AUTOSAR XML (schema 314)
package /ComponentType
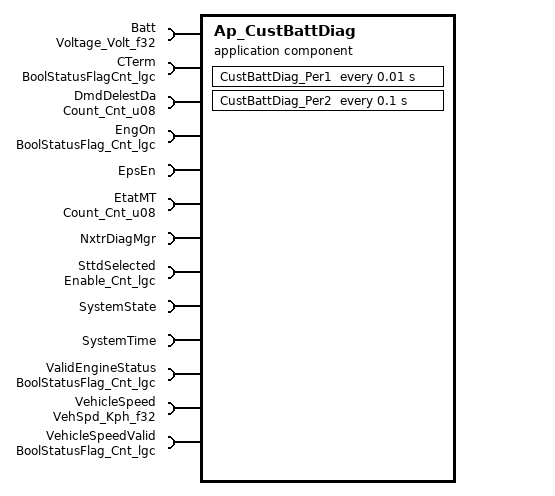
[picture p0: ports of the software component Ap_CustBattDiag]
  application software component type Ap_CustBattDiag
    13 x require port:
      Batt: unqueued-receiver-com-spec{data-element=Volt_f32, init-value=D_ZERO_ULS_F32}, required-interface=Voltage_Volt_f32
      CTerm: unqueued-receiver-com-spec{data-element=Cnt_lgc, init-value=D_FALSE_CNT_LGC}, required-interface=BoolStatusFlagCnt_lgc
      DmdDelestDa: unqueued-receiver-com-spec{data-element=Cnt_u08, init-value=D_ZERO_CNT_U8}, required-interface=Count_Cnt_u08
      EngOn: unqueued-receiver-com-spec{data-element=Cnt_lgc, init-value=D_FALSE_CNT_LGC}, required-interface=BoolStatusFlag_Cnt_lgc
      EpsEn: client-com-spec=OP_GET, required-interface=EpsEn
      EtatMT: unqueued-receiver-com-spec{data-element=Cnt_u08, init-value=D_ZERO_CNT_U8}, required-interface=Count_Cnt_u08
      NxtrDiagMgr: required-com-specs=[GetNTCActive, GetNTCFailed, GetNTCStatus, SetNTCStatus], required-interface=NxtrDiagMgr
      SttdSelected: unqueued-receiver-com-spec{data-element=Cnt_lgc, init-value=D_FALSE_CNT_LGC}, required-interface=Enable_Cnt_lgc
      SystemState: required-interface=SystemState
      SystemTime: required-interface=SystemTime
        required-com-specs:
          DtrmnElapsedTime_mS_u16
          DtrmnElapsedTime_mS_u32
          DtrmnElapsedTime_uS_u16
          DtrmnElapsedTime_uS_u32
          GetSystemTime_mS_u32
          GetSystemTime_uS_u32
      ValidEngineStatus: unqueued-receiver-com-spec{data-element=Cnt_lgc, init-value=D_FALSE_CNT_LGC}, required-interface=BoolStatusFlag_Cnt_lgc
      VehicleSpeed: unqueued-receiver-com-spec{data-element=Kph_f32, init-value=D_ZERO_ULS_F32}, required-interface=VehSpd_Kph_f32
      VehicleSpeedValid: unqueued-receiver-com-spec{data-element=Cnt_lgc, init-value=D_FALSE_CNT_LGC}, required-interface=BoolStatusFlag_Cnt_lgc
  internal behavior Ap_CustBattDiag_InternalBehavior: component=Ap_CustBattDiag
    timing event TMT_CustBattDiag_Per1: start-on-event=CustBattDiag_Per1, period=0.01
    timing event TMT_CustBattDiag_Per2: start-on-event=CustBattDiag_Per2, period=0.1
    port-api-options:
      enable-take-address=false, indirect-api=false, port=Batt
      enable-take-address=false, indirect-api=false, port=CTerm
      enable-take-address=false, indirect-api=false, port=DmdDelestDa
      enable-take-address=false, indirect-api=false, port=EngOn
      enable-take-address=false, indirect-api=false, port=EpsEn
      enable-take-address=false, indirect-api=false, port=EtatMT
      enable-take-address=false, indirect-api=false, port=NxtrDiagMgr
      enable-take-address=false, indirect-api=false, port=SttdSelected
      enable-take-address=false, indirect-api=false, port=SystemState
      enable-take-address=false, indirect-api=false, port=SystemTime
      enable-take-address=false, indirect-api=false, port=ValidEngineStatus
      enable-take-address=false, indirect-api=false, port=VehicleSpeed
      enable-take-address=false, indirect-api=false, port=VehicleSpeedValid
    runnable CustBattDiag_Per1
      data read access READ_Batt_Volt_f32: data-element=Batt.Volt_f32
      sync call SC_NxtrDiagMgr_SetNTCStatus: operation=NxtrDiagMgr.SetNTCStatus, timeout=0
      sync call SC_SystemTime_DtrmnElapsedTime_mS_u16: operation=SystemTime.DtrmnElapsedTime_mS_u16, timeout=0
      sync call SC_SystemTime_GetSystemTime_mS_u32: operation=SystemTime.GetSystemTime_mS_u32, timeout=0
    runnable CustBattDiag_Per2
      9 x data read access:
        READ_Batt_Volt_f32: data-element=Batt.Volt_f32
        READ_CTerm_Cnt_lgc: data-element=CTerm.Cnt_lgc
        READ_DmdDelestDa_Cnt_u08: data-element=DmdDelestDa.Cnt_u08
        READ_EngOn_Cnt_lgc: data-element=EngOn.Cnt_lgc
        READ_EtatMT_Cnt_u08: data-element=EtatMT.Cnt_u08
        READ_SttdSelected_Cnt_lgc: data-element=SttdSelected.Cnt_lgc
        READ_ValidEngineStatus_Cnt_lgc: data-element=ValidEngineStatus.Cnt_lgc
        READ_VehicleSpeed_Kph_f32: data-element=VehicleSpeed.Kph_f32
        READ_VehicleSpeedValid_Cnt_lgc: data-element=VehicleSpeedValid.Cnt_lgc
      5 x sync call, all with timeout=0:
        SC_EpsEn_OP_GET: operation=EpsEn.OP_GET
        SC_NxtrDiagMgr_GetNTCFailed: operation=NxtrDiagMgr.GetNTCFailed
        SC_NxtrDiagMgr_SetNTCStatus: operation=NxtrDiagMgr.SetNTCStatus
        SC_SystemTime_DtrmnElapsedTime_mS_u32: operation=SystemTime.DtrmnElapsedTime_mS_u32
        SC_SystemTime_GetSystemTime_mS_u32: operation=SystemTime.GetSystemTime_mS_u32
  swc implementation Ap_CustBattDiag_Implementation: behavior=Ap_CustBattDiag_InternalBehavior
    code-descriptors:
      code Code: type=SRC
